# RockChip_RK3588 register map
Vendor: RockChip Electronics Co., Ltd.; Series: RK3588; File version: 0.1
RockChip RK3588 System-on-Chip
Registers are 32-bit, read-write, no defined reset value unless marked. A register's access mark holds for its fields unless they carry their own. Offsets are from the block's base; lines under a group give offsets from that group; [hi:lo] are bit positions; {n}, {i} and the like mark numbered series; 'fields as' and 'values as' point back to an identical list; <NAME> marks a mode.

## Memory map
0xFD582000 SGRF_PMU1 size 0x2000
0xFD586000 SGRF_BUS size 0x1000
0xFD587000 SGRF_DSU size 0x1000
0xFD588000 GRF_PMU0 size 0x2000
0xFD58A000 GRF_PMU1 size 0x2000
0xFD58C000 GRF_SYS size 0x4000
0xFD590000 GRF_BIGCORE0 size 0x2000
0xFD592000 GRF_BIGCORE1 size 0x2000
0xFD594000 GRF_LITCORE size 0x4000
0xFD598000 GRF_DSU size 0x4000
0xFD59C000 GRF_DDR01 size 0x1000
0xFD59D000 GRF_DDR23 size 0x1000
0xFD59E000 GRF_CENTER size 0x2000
0xFD5A0000 GRF_GPU size 0x2000
0xFD5B4000 GRF_CSIDPHY0 size 0x1000
0xFD5B5000 GRF_CSIDPHY1 size 0x1000
0xFD5F0000 IOC_PMU1 size 0x4000
0xFD5F4000 IOC_PMU2 size 0x4000
0xFD5F8000 IOC_BUS size 0x1000
0xFD5F9000 IOC_VCCIO1_4 size 0x1000
0xFD5FA000 IOC_VCCIO3_5 size 0x1000
0xFD5FB000 IOC_VCCIO2 size 0x1000
0xFD5FC000 IOC_VCCIO6 size 0x1000
0xFD5FD000 IOC_EMMC size 0x1000
0xFD7C0000 CRU size 0x8000
0xFD7C8000 CRU_PHP_PPLL size 0x8000
0xFD7D0000 CRU_SECURE size 0x8000
0xFD7D8000 CRU_SBUS size 0x8000
0xFD7E0000 CRU_SECURE_PMU1 size 0x10000
0xFD7F0000 CRU_PMU1 size 0x10000
0xFD800000 CRU_DDRPHY0 size 0x4000
0xFD804000 CRU_DDRPHY1 size 0x4000
0xFD808000 CRU_DDRPHY2 size 0x4000
0xFD80C000 CRU_DDRPHY3 size 0x4000
0xFD810000 CRU_BIGCORE0 size 0x2000
0xFD812000 CRU_BIGCORE1 size 0x2000
0xFD818000 CRU_DSU size 0x4000
0xFD8D0000 PMU size 0x10000
0xFE010000 FIREWALL_DSUDDR size 0x8000
0xFE030000 FIREWALL_DDR size 0x8000
0xFE038000 FIREWALL_SYSMEM size 0x8000
0xFE380000 KEYLADDER_S size 0x10000

## CRU_SECURE_PMU1
Base 0xFD7E0000
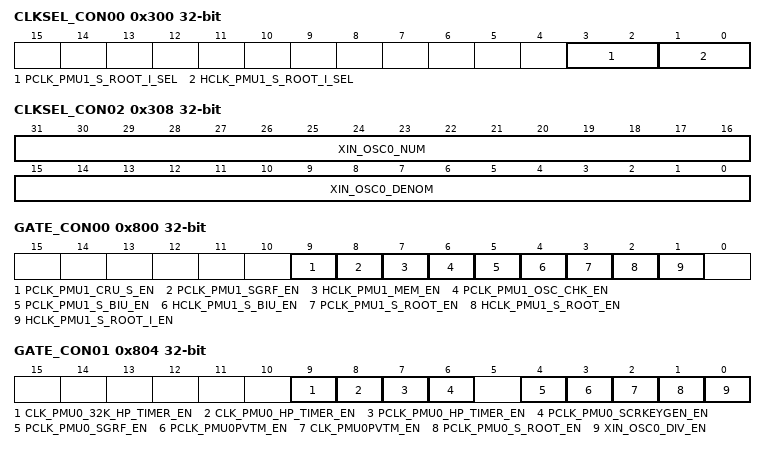
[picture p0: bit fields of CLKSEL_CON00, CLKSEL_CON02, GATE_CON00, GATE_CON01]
0x300 CLKSEL_CON00 — Internal clock select and division register 0
  [3:2] PCLK_PMU1_S_ROOT_I_SEL — pclk_pmu1_s_root_i clock mux.
    0=CLK_MATRIX_PMU1_100M_SRC; 1=CLK_MATRIX_PMU1_50M_SRC; 2=XIN_OSC0_FUNC
  [1:0] HCLK_PMU1_S_ROOT_I_SEL — hclk_pmu1_s_root_i_sel clock mux.
    0=CLK_MATRIX_PMU1_200M_SRC; 1=CLK_MATRIX_PMU1_100M_SRC; 2=CLK_MATRIX_PMU1_50M_SRC; 3=XIN_OSC0_FUNC
0x308 CLKSEL_CON02 — Internal clock select and division register 2
  [31:16] XIN_OSC0_NUM — xin_osc0_div fraction division register. High 16-bit for numerator.
  [15:0] XIN_OSC0_DENOM — xin_osc0_div fraction division register. Low 16-bit for denominator.
0x800 GATE_CON00 — Internal clock gate and division register 0
  [all] fields
    0=ENABLE; 1=DISABLE
  [9] PCLK_PMU1_CRU_S_EN — pclk_pmu1_cru_s clock gating control.
  [8] PCLK_PMU1_SGRF_EN — pclk_pmu1_sgrf clock gating control.
  [7] HCLK_PMU1_MEM_EN — hclk_pmu1_mem clock gating control.
  [6] PCLK_PMU1_OSC_CHK_EN — pclk_pmu1_osc_chk clock gating control.
  [5] PCLK_PMU1_S_BIU_EN — pclk_pmu1_s_biu clock gating control.
  [4] HCLK_PMU1_S_BIU_EN — hclk_pmu1_s_biu clock gating control.
  [3] PCLK_PMU1_S_ROOT_EN — pclk_pmu1_s_root_i clock gating control.
  [2] HCLK_PMU1_S_ROOT_EN — hclk_pmu1_s_root clock gating control.
  [1] HCLK_PMU1_S_ROOT_I_EN — hclk_pmu1_s_root_i clock gating control.
0x804 GATE_CON01 — Internal clock gate and division register 1
  [all] fields
    0=ENABLE; 1=DISABLE
  [9] CLK_PMU0_32K_HP_TIMER_EN — clk_pmu0_32k_hp_timer clock gating control.
  [8] CLK_PMU0_HP_TIMER_EN — clk_pmu0_hp_timer clock gating control.
  [7] PCLK_PMU0_HP_TIMER_EN — pclk_pmu0_hp_timer clock gating control.
  [6] PCLK_PMU0_SCRKEYGEN_EN — pclk_pmu0_scrkeygen clock gating control.
  [4] PCLK_PMU0_SGRF_EN — pclk_pmu0_sgrf clock gating control.
  [3] PCLK_PMU0PVTM_EN — pclk_pmu0pvtm clock gating control.
  [2] CLK_PMU0PVTM_EN — clk_pmu0pvtm clock gating control.
  [1] PCLK_PMU0_S_ROOT_EN — pclk_pmu0_s_root clock gating control.
  [0] XIN_OSC0_DIV_EN — xin_osc0_div clock gating control.
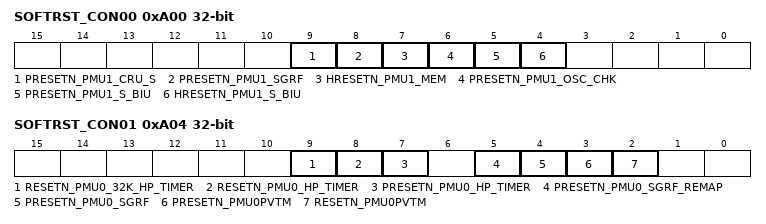
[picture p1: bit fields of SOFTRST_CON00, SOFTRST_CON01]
0xA00 SOFTRST_CON00 — Internal clock reset register 0
  [9] PRESETN_PMU1_CRU_S — When high, reset relative logic
  [8] PRESETN_PMU1_SGRF — When high, reset relative logic
  [7] HRESETN_PMU1_MEM — When high, reset relative logic
  [6] PRESETN_PMU1_OSC_CHK — When high, reset relative logic
  [5] PRESETN_PMU1_S_BIU — When high, reset relative logic
  [4] HRESETN_PMU1_S_BIU — When high, reset relative logic
0xA04 SOFTRST_CON01 — Internal clock reset register 1
  [9] RESETN_PMU0_32K_HP_TIMER — When high, reset relative logic
  [8] RESETN_PMU0_HP_TIMER — When high, reset relative logic
  [7] PRESETN_PMU0_HP_TIMER — When high, reset relative logic
  [5] PRESETN_PMU0_SGRF_REMAP — When high, reset relative logic
  [4] PRESETN_PMU0_SGRF — When high, reset relative logic
  [3] PRESETN_PMU0PVTM — When high, reset relative logic
  [2] RESETN_PMU0PVTM — When high, reset relative logic
